# MK70F15WS register map
File version: 1.6
Registers are 32-bit, read-write, reset 0x0 unless marked. A register's access mark holds for its fields unless they carry their own. Offsets are from the block's base; [hi:lo] are bit positions; {n}, {i} and the like mark numbered series; 'fields as' and 'values as' point back to an identical list.

## PORTA — Pin Control and Interrupts
Base 0x40049000; register names take the prefix PORTA_
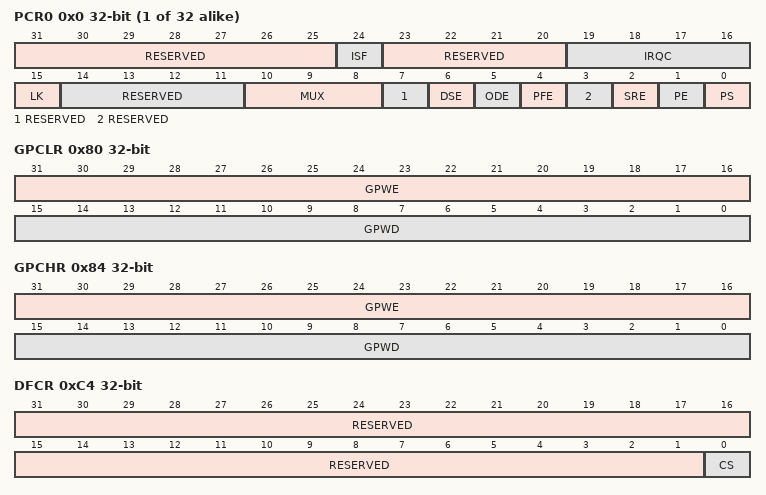
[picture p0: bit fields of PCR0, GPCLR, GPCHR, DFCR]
{0x0+4i} PCR{i} (i=0..31) — Pin Control Register n
  [31:25] RESERVED ro
  [24] ISF — Interrupt Status Flag
    0=Configured interrupt has not been detected; 1=Configured interrupt has been detected. If pin is configured to generate a DMA request then the corresponding flag will be cleared automatically at the completion of the requested DMA transfer, otherwise the flag remains set until a logic one is written to that flag. If configured for a level sensitive interrupt that remains asserted then flag will set again immediately.
  [23:20] RESERVED ro
  [19:16] IRQC — Interrupt Configuration
    0=Interrupt/DMA Request disabled; 1=DMA Request on rising edge; 2=DMA Request on falling edge; 3=DMA Request on either edge; 8=Interrupt when logic zero; 9=Interrupt on rising edge; 10=Interrupt on falling edge; 11=Interrupt on either edge; 12=Interrupt when logic one
  [15] LK — Lock Register
    0=Pin Control Register bits [15:0] are not locked; 1=Pin Control Register bits [15:0] are locked and cannot be updated until the next System Reset
  [14:11] RESERVED ro
  [10:8] MUX — Pin Mux Control
    0=Pin Disabled (Analog); 1=Alternative 1 (GPIO); {v}=Alternative {v} (chip specific) (v=2..6); 7=Alternative 7 (chip specific / JTAG / NMI)
  [7] RESERVED ro
  [6] DSE — Drive Strength Enable
    0=Low drive strength is configured on the corresponding pin, if pin is configured as a digital output; 1=High drive strength is configured on the corresponding pin, if pin is configured as a digital output
  [5] ODE — Open Drain Enable
    0=Open Drain output is disabled on the corresponding pin; 1=Open Drain output is enabled on the corresponding pin, provided pin is configured as a digital output
  [4] PFE — Passive Filter Enable
    0=Passive Input Filter is disabled on the corresponding pin; 1=Passive Input Filter is enabled on the corresponding pin, provided pin is configured as a digital input. A low pass filter (10 MHz to 30 MHz bandwidth) is enabled on the digital input path. Disable the Passive Input Filter when supporting high speed interfaces (> 2 MHz) on the pin.
  [3] RESERVED ro
  [2] SRE — Slew Rate Enable
    0=Fast slew rate is configured on the corresponding pin, if pin is configured as a digital output; 1=Slow slew rate is configured on the corresponding pin, if pin is configured as a digital output
  [1] PE — Pull Enable
    0=Internal pull-up or pull-down resistor is not enabled on the corresponding pin; 1=Internal pull-up or pull-down resistor is enabled on the corresponding pin, provided pin is configured as a digital input
  [0] PS — Pull Select
    0=Internal pull-down resistor is enabled on the corresponding pin, if the corresponding Port Pull Enable Register bit is set; 1=Internal pull-up resistor is enabled on the corresponding pin, if the corresponding Port Pull Enable Register bit is set
0x80 GPCLR wo — Global Pin Control Low Register
  [31:16] GPWE — Global Pin Write Enable
  [15:0] GPWD — Global Pin Write Data
0x84 GPCHR wo — Global Pin Control High Register
  fields as GPCLR
0xA0 ISFR — Interrupt Status Flag Register
  [31:0] ISF — Interrupt Status Flag
    0=Configured interrupt has not been detected; 1=Configured interrupt has been detected. If pin is configured to generate a DMA request then the corresponding flag will be cleared automatically at the completion of the requested DMA transfer, otherwise the flag remains set until a logic one is written to the flag. If configured for a level sensitive interrupt and the pin remains asserted then the flag will set again immediately after it is cleared.
0xC0 DFER — Digital Filter Enable Register
  [31:0] DFE — Digital Filter Enable
    0=Digital Filter is disabled on the corresponding pin and output of the digital filter is reset to zero.Each bit in the field enables the digital filter of the same number as the bit; 1=Digital Filter is enabled on the corresponding pin, provided pin is configured as a digital input
0xC4 DFCR — Digital Filter Clock Register
  [31:1] RESERVED ro
  [0] CS — Clock Source
    0=Digital Filters are clocked by the bus clock; 1=Digital Filters are clocked by the 1 kHz LPO clock
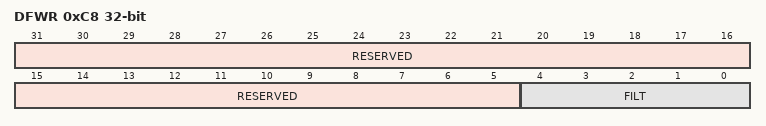
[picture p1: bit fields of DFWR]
0xC8 DFWR — Digital Filter Width Register
  [31:5] RESERVED ro
  [4:0] FILT — Filter Length

## PORTB — Pin Control and Interrupts
Base 0x4004A000; register names take the prefix PORTB_
Registers as PORTA.

## PORTC — Pin Control and Interrupts
Base 0x4004B000; register names take the prefix PORTC_
Registers as PORTA.

## PORTD — Pin Control and Interrupts
Base 0x4004C000; register names take the prefix PORTD_
Registers as PORTA.

## PORTE — Pin Control and Interrupts
Base 0x4004D000; register names take the prefix PORTE_
Registers as PORTA.

## PORTF — Pin Control and Interrupts
Base 0x4004E000; register names take the prefix PORTF_
Registers as PORTA.
